# TLE9868 register map
Vendor: Infineon; File version: 3.6
CPU: CM3 r0p0, little endian, no MPU, no FPU, 4 interrupt priority bits
Registers are 32-bit, read-write, reset 0x0 unless marked. A register's access mark holds for its fields unless they carry their own. Offsets are from the block's base; [hi:lo] are bit positions; {n}, {i} and the like mark numbered series; 'fields as' and 'values as' point back to an identical list.

## PORT — GPIO PORTs
Base 0x48028000
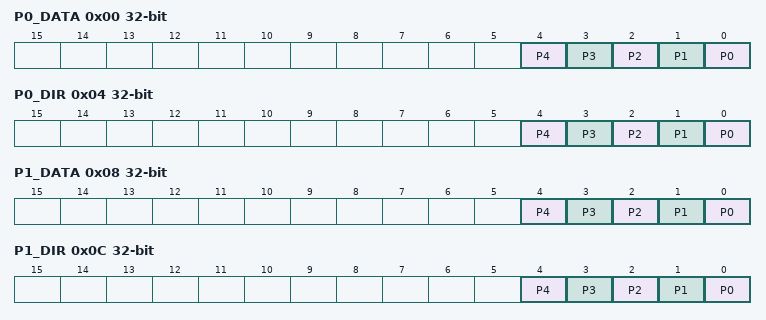
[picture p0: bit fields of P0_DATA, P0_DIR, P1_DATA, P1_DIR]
0x00 P0_DATA reset not defined — Port 0 Data Register
  [all] fields
    0=Port 0 pin n data value = 0; 1=Port 0 pin n data value = 1
  [n] P{n} (n=0..4) — Port 0 Pin {n} Data Value
0x04 P0_DIR — Port 0 Direction Register
  [all] fields
    0=Direction is set to input (default); 1=Direction is set to output
  [n] P{n} (n=0..4) — Port 0 Pin {n} Direction Control
0x08 P1_DATA reset not defined — Port 1 Data Register
  [all] fields
    0=Port 1 pin n data value = 0; 1=Port 1 pin n data value = 1
  [n] P{n} (n=0..4) — Port 1 Pin {n} Data Value
0x0C P1_DIR — Port 1 Direction Register
  [all] fields
    values as the fields of P0_DIR
  [n] P{n} (n=0..4) — Port 1 Pin {n} Direction Control
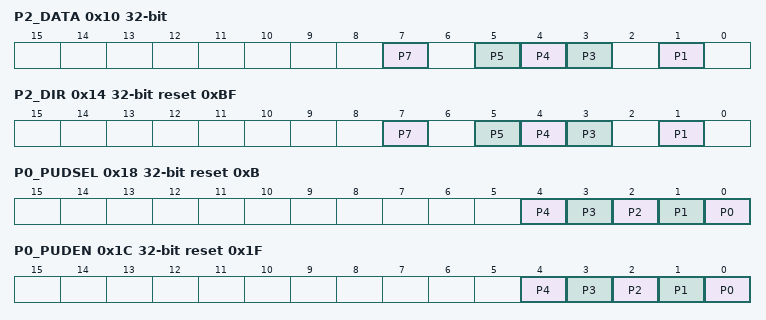
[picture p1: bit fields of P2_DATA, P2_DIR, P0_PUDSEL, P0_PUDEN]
0x10 P2_DATA ro reset not defined — Port 2 Data Register
  [all] fields
    0=Port 2 pin n data value = 0; 1=Port 2 pin n data value = 1
  [7] P7 — Port 2 Pin 7 Data Value
  [5] P5 — Port 2 Pin 5 Data Value
  [4] P4 — Port 2 Pin 4 Data Value
  [3] P3 — Port 2 Pin 3 Data Value
  [1] P1 — Port 2 Pin 1 Data Value
0x14 P2_DIR reset 0xBF — Port 2 Direction Register
  [all] fields
    0=Input driver is enabled; 1=Input driver is disabled (default)
  [7] P7 — Port 2 Pin 7 Driver Control
  [5] P5 — Port 2 Pin 5 Driver Control
  [4] P4 — Port 2 Pin 4 Driver Control
  [3] P3 — Port 2 Pin 3 Driver Control
  [1] P1 — Port 2 Pin 1 Driver Control
0x18 P0_PUDSEL reset 0xB — Port 0 Pull-Up/Pull-Down Select Register
  [all] fields
    0=Pull-down device is selected; 1=Pull-up device is selected
  [n] P{n} (n=0..4) — Pull-Up/Pull-Down Select Port 0 Bit {n}
0x1C P0_PUDEN reset 0x1F — Port 0 Pull-Up/Pull-Down Enable Register
  [all] fields
    0=Pull-up or Pull-down device is disabled; 1=Pull-up or Pull-down device is enabled
  [n] P{n} (n=0..4) — Pull-Up/Pull-Down Enable at Port 0 Bit {n}
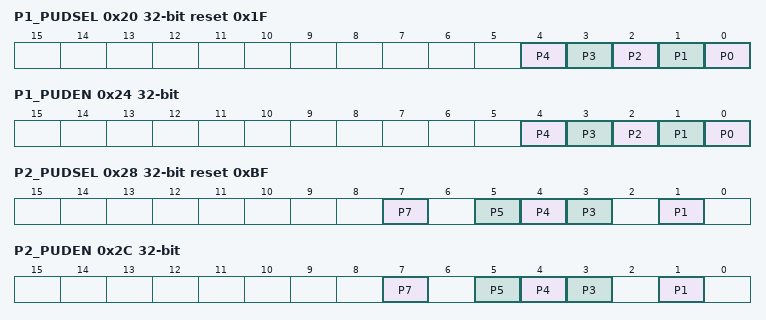
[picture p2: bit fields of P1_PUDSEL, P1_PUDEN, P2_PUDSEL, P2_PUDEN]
0x20 P1_PUDSEL reset 0x1F — Port 1 Pull-Up/Pull-Down Select Register
  [all] fields
    0=Pull-down device is selected; 1=Pull-up device is selected (default)
  [n] P{n} (n=0..4) — Pull-Up/Pull-Down Select Port 1 Bit {n}
0x24 P1_PUDEN — Port 1 Pull-Up/Pull-Down Enable Register
  [all] fields
    0=Pull-up or Pull-down device is disabled (default); 1=Pull-up or Pull-down device is enabled
  [n] P{n} (n=0..4) — Pull-Up/Pull-Down Enable at Port 1 Bit {n}
0x28 P2_PUDSEL reset 0xBF — Port 2 Pull-Up/Pull-Down Select Register
  [all] fields
    values as the fields of P1_PUDSEL
  [7] P7 — Pull-Up/Pull-Down Select Port 2 Bit 7
  [5] P5 — Pull-Up/Pull-Down Select Port 2 Bit 5
  [4] P4 — Pull-Up/Pull-Down Select Port 2 Bit 4
  [3] P3 — Pull-Up/Pull-Down Select Port 2 Bit 3
  [1] P1 — Pull-Up/Pull-Down Select Port 2 Bit 1
0x2C P2_PUDEN — Port 2 Pull-Up/Pull-Down Enable Register
  [all] fields
    values as the fields of P1_PUDEN
  [7] P7 — Pull-Up/Pull-Down Enable at Port 2 Bit 7
  [5] P5 — Pull-Up/Pull-Down Enable at Port 2 Bit 5
  [4] P4 — Pull-Up/Pull-Down Enable at Port 2 Bit 4
  [3] P3 — Pull-Up/Pull-Down Enable at Port 2 Bit 3
  [1] P1 — Pull-Up/Pull-Down Enable at Port 2 Bit 1
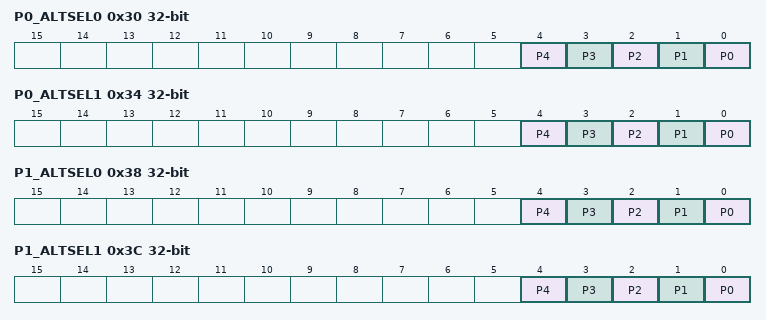
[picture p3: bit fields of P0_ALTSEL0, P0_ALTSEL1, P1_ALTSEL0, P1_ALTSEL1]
0x30 P0_ALTSEL0 — Port 0 Alternate Select Register
  [n] P{n} (n=0..4) — Alternate Select Port 0 Bit {n}
0x34 P0_ALTSEL1 — Port 0 Alternate Select Register
  [n] P{n} (n=0..4) — Alternate Select Port 0 Bit {n}
0x38 P1_ALTSEL0 — Port 1 Alternate Select Register
  [n] P{n} (n=0..4) — Alternate Select Port 1 Bit {n}
0x3C P1_ALTSEL1 — Port 1 Alternate Select Register
  [n] P{n} (n=0..4) — Alternate Select Port 1 Bit {n}
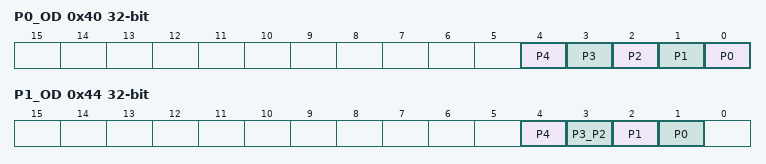
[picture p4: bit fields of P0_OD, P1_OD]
0x40 P0_OD — Port 0 Open Drain Control Register
  [all] fields
    0=Normal Mode, output is actively driven for 0 and 1 state (default); 1=Open Drain Mode, output is actively driven only for 0 state
  [n] P{n} (n=0..4) — Port 0 Pin {n} Open Drain Mode
0x44 P1_OD — Port 1 Open Drain Control Register
  [all] fields
    values as the fields of P0_OD
  [4] P4 — P1.4 Open Drain Mode
  [3] P3_P2 — P1.3/P1.2 Open Drain Mode
  [2] P1 — P1.1 Open Drain Mode
  [1] P0 — P1.0 Open Drain Mode
